# M369 register map
File version: 0.1
CPU: 
Registers are 32-bit, read-write, reset 0x0 unless marked. A register's access mark holds for its fields unless they carry their own. Offsets are from the block's base; [hi:lo] are bit positions; {n}, {i} and the like mark numbered series.

## PN — General Purpose Input_Output Port (PN)
Base 0x400C0D00
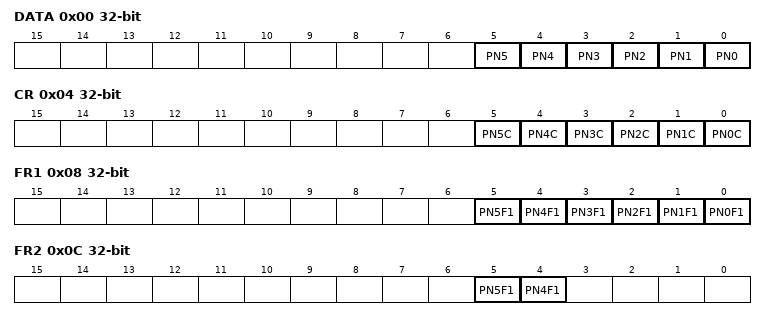
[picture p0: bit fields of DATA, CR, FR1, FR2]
0x00 DATA — PN Data Register
  [n] PN{n} (n=0..5)
0x04 CR — PN Control Register
  [n] PN{n}C (n=0..5)
0x08 FR1 — PN Function Register 1
  [n] PN{n}F1 (n=0..5)
0x0C FR2 — PN Function Register 2
  [5] PN5F1, [4] PN4F1
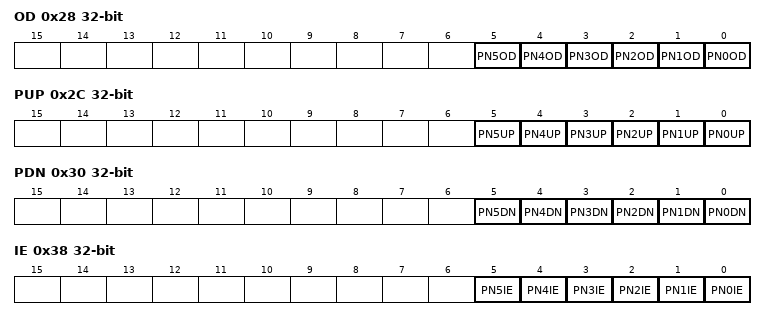
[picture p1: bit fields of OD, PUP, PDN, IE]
0x28 OD — PN Open Drain Control Register
  [n] PN{n}OD (n=0..5)
0x2C PUP — PN Pull-Up Control Register
  [n] PN{n}UP (n=0..5)
0x30 PDN — PN Pull-Down Control Register
  [n] PN{n}DN (n=0..5)
0x38 IE — PN Input Enable Control Register
  [n] PN{n}IE (n=0..5)

## TB0 — 16-bit Timer_Event Counter (TB)
Base 0x400C4000
Same registers: TB1 0x400C4100, TB2 0x400C4200, TB3 0x400C4300, TB4 0x400C4400, TB5 0x400C4500, TB6 0x400C4600, TB7 0x400C4700
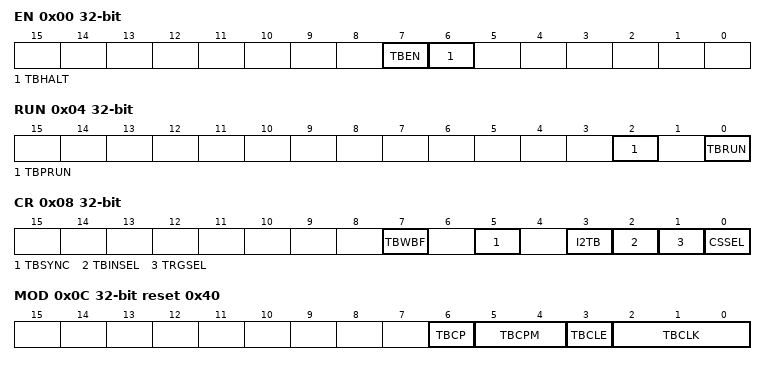
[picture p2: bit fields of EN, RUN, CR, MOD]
0x00 EN — TB Enable Register
  [7] TBEN, [6] TBHALT
0x04 RUN — TB RUN Register
  [2] TBPRUN, [0] TBRUN
0x08 CR — TB Control Register
  [7] TBWBF, [5] TBSYNC, [3] I2TB, [2] TBINSEL, [1] TRGSEL, [0] CSSEL
0x0C MOD reset 0x40 — TB Mode Register
  [6] TBCP wo, [5:4] TBCPM, [3] TBCLE, [2:0] TBCLK
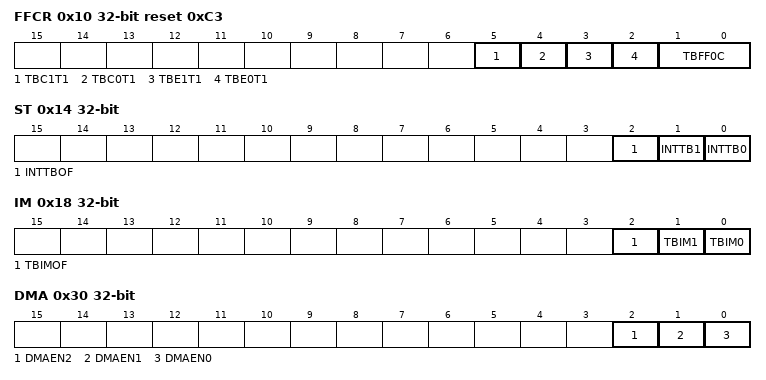
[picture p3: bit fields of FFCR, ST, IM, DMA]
0x10 FFCR reset 0xC3 — TB Flip-Flop Control Register
  [5] TBC1T1, [4] TBC0T1, [3] TBE1T1, [2] TBE0T1, [1:0] TBFF0C
0x14 ST ro — TB Status Register
  [2] INTTBOF, [1] INTTB1, [0] INTTB0
0x18 IM — TB Interrupt Mask Register
  [2] TBIMOF, [1] TBIM1, [0] TBIM0
0x1C UC ro — TB Read Capture Register
  [15:0] TBUC
0x20 RG0 — TB RG0 Timer Register
  [15:0] TBRG0
0x24 RG1 — TB RG1 Timer Register
  [15:0] TBRG1
0x28 CP0 ro (reset mask 0xFFFF0000) — TB CP0 Capture Register
  [15:0] TBCP0
0x2C CP1 ro (reset mask 0xFFFF0000) — TB CP1 Capture Register
  [15:0] TBCP1
0x30 DMA (reset mask 0xFFFFFFF8) — TB DMA Enable Register
  [2] DMAEN2, [1] DMAEN1, [0] DMAEN0

## MT0 — 16-bit Multi-Purpose Timer (MPT-TMR_IGBT)
Base 0x400C7000
Same registers: MT1 0x400C7100, MT2 0x400C7200, MT3 0x400C7300
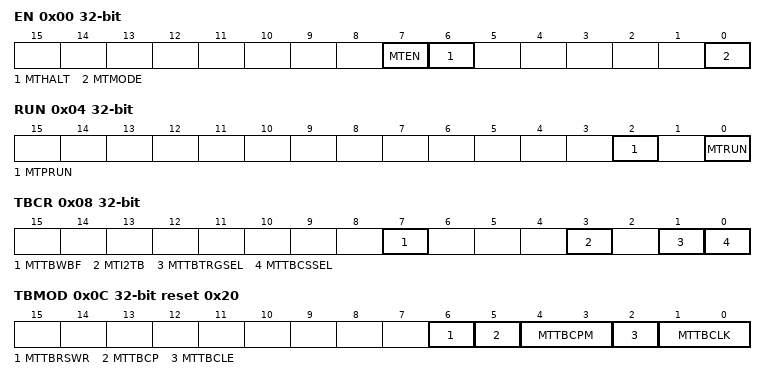
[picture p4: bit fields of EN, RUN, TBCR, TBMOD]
0x00 EN — MPT Enable Register
  [7] MTEN, [6] MTHALT, [0] MTMODE
0x04 RUN — MPT RUN Register
  [2] MTPRUN, [0] MTRUN
0x08 TBCR — MPT Control Register
  [7] MTTBWBF, [3] MTI2TB, [1] MTTBTRGSEL, [0] MTTBCSSEL
0x0C TBMOD reset 0x20 — MPT Mode Register
  [6] MTTBRSWR, [5] MTTBCP wo, [4:3] MTTBCPM, [2] MTTBCLE, [1:0] MTTBCLK
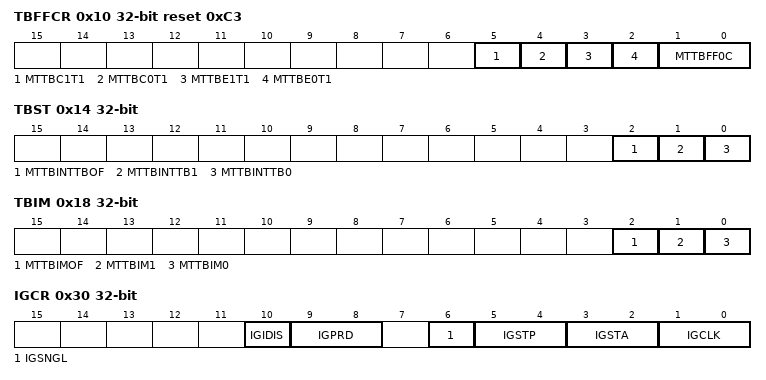
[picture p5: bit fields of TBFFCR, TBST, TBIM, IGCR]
0x10 TBFFCR reset 0xC3 — MPT Flip-Flop Control Register
  [5] MTTBC1T1, [4] MTTBC0T1, [3] MTTBE1T1, [2] MTTBE0T1, [1:0] MTTBFF0C
0x14 TBST ro — MPT Status Register
  [2] MTTBINTTBOF, [1] MTTBINTTB1, [0] MTTBINTTB0
0x18 TBIM — MPT Interrupt Mask Register
  [2] MTTBIMOF, [1] MTTBIM1, [0] MTTBIM0
0x1C TBUC ro — MPT Read Capture Register
  [15:0] MTUC
0x20 RG0 — MPT RG0 Timer Register
  [15:0] MTRG0
0x24 RG1 — MPT RG1 Timer Register
  [15:0] MTRG1
0x28 CP0 ro — MPT CP0 Capture Register
  [15:0] MTCP0
0x2C CP1 ro — MPT CP1 Capture Register
  [15:0] MTCP1
0x30 IGCR — IGBT Control Register
  [10] IGIDIS, [9:8] IGPRD, [6] IGSNGL, [5:4] IGSTP, [3:2] IGSTA, [1:0] IGCLK
0x34 IGRESTA wo — IGBT Timer Restart Register
  [0] IGRESTA
0x38 IGST ro — IGBT Timer Status Register
  [0] IGST
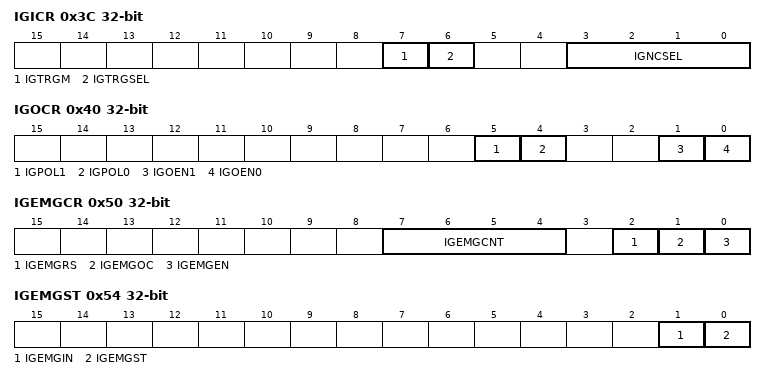
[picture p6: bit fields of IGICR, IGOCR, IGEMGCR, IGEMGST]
0x3C IGICR — IGBT Input Control Register
  [7] IGTRGM, [6] IGTRGSEL, [3:0] IGNCSEL
0x40 IGOCR — IGBT Output Control Register
  [5] IGPOL1, [4] IGPOL0, [1] IGOEN1, [0] IGOEN0
{0x3C+4i} IGRG{i} (i=2..4) — IGBT RG{i} Timer Register
  [15:0] IGRG{i}
0x50 IGEMGCR — IGBT EMG Control Register
  [7:4] IGEMGCNT, [2] IGEMGRS wo, [1] IGEMGOC, [0] IGEMGEN
0x54 IGEMGST ro — IGBT EMG Status Register
  [1] IGEMGIN, [0] IGEMGST

## RTC — Real Time Clock (RTC)
Base 0x400CC000
0x00 SECR 8-bit (reset mask 0x80) — RTC Second Column Register
  [6:0] SE
0x01 MINR 8-bit (reset mask 0x80) — RTC Minute Column Register
  [6:0] MI
0x02 HOURR 8-bit (reset mask 0xC0) — RTC Hour Column Register
  [5:0] HO
0x04 DAYR 8-bit (reset mask 0xF8) — RTC Day of the Week Column Register
  [2:0] WE
0x05 DATER 8-bit (reset mask 0xC0) — RTC Day Column Register
  [5:0] DA
0x06 MONTHR_A 8-bit (reset mask 0xE0) — RTC Month Column Register
  [4:0] MO
0x06 MONTHR_B 8-bit (reset mask 0xFE) (RTC_MONTHR view) — RTC Month Column Register
  [0] MO0
0x07 YEARR_A 8-bit reset not defined — RTC Year Column Register
  [7:0] YE
0x07 YEARR_B 8-bit (reset mask 0xFC) (RTC_YEARR view) — RTC Year Column Register
  [1:0] LEAP
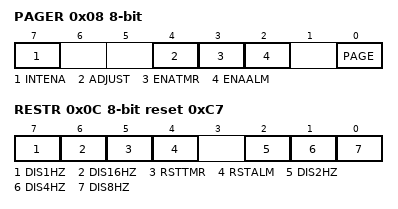
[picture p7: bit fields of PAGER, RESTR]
0x08 PAGER 8-bit (reset mask 0xF3) — RTC PAGE Register
  [7] INTENA, [4] ADJUST, [3] ENATMR, [2] ENAALM, [0] PAGE
0x0C RESTR 8-bit reset 0xC7 — RTC Reset Register
  [7] DIS1HZ, [6] DIS16HZ, [5] RSTTMR, [4] RSTALM, [2] DIS2HZ, [1] DIS4HZ, [0] DIS8HZ
